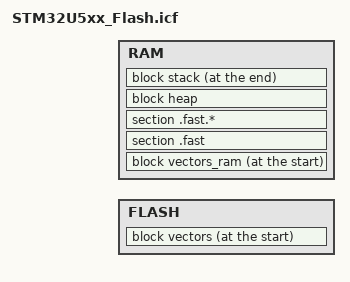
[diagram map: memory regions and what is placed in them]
/*********************************************************************
*                    SEGGER Microcontroller GmbH                     *
*                        The Embedded Experts                        *
**********************************************************************
*                                                                    *
*            (c) 2014 - 2024 SEGGER Microcontroller GmbH             *
*                                                                    *
*       www.segger.com     Support: support@segger.com               *
*                                                                    *
**********************************************************************
*                                                                    *
* All rights reserved.                                               *
*                                                                    *
* Redistribution and use in source and binary forms, with or         *
* without modification, are permitted provided that the following    *
* condition is met:                                                  *
*                                                                    *
* - Redistributions of source code must retain the above copyright   *
*   notice, this condition and the following disclaimer.             *
*                                                                    *
* THIS SOFTWARE IS PROVIDED BY THE COPYRIGHT HOLDERS AND             *
* CONTRIBUTORS "AS IS" AND ANY EXPRESS OR IMPLIED WARRANTIES,        *
* INCLUDING, BUT NOT LIMITED TO, THE IMPLIED WARRANTIES OF           *
* MERCHANTABILITY AND FITNESS FOR A PARTICULAR PURPOSE ARE           *
* DISCLAIMED. IN NO EVENT SHALL SEGGER Microcontroller BE LIABLE FOR *
* ANY DIRECT, INDIRECT, INCIDENTAL, SPECIAL, EXEMPLARY, OR           *
* CONSEQUENTIAL DAMAGES (INCLUDING, BUT NOT LIMITED TO, PROCUREMENT  *
* OF SUBSTITUTE GOODS OR SERVICES; LOSS OF USE, DATA, OR PROFITS;    *
* OR BUSINESS INTERRUPTION) HOWEVER CAUSED AND ON ANY THEORY OF      *
* LIABILITY, WHETHER IN CONTRACT, STRICT LIABILITY, OR TORT          *
* (INCLUDING NEGLIGENCE OR OTHERWISE) ARISING IN ANY WAY OUT OF THE  *
* USE OF THIS SOFTWARE, EVEN IF ADVISED OF THE POSSIBILITY OF SUCH   *
* DAMAGE.                                                            *
*                                                                    *
**********************************************************************
-------------------------- END-OF-HEADER -----------------------------

File    : STM32U5xx_Flash.icf
Purpose : STM32U5xx linker script for application placement in Flash,
          for use with the SEGGER Linker.
Maps    : STM32U535CBTx, STM32U535CBTxQ, STM32U535CBUx, STM32U535CBUxQ, 
          STM32U535CCTx, STM32U535CCTxQ, STM32U535CCUx, STM32U535CCUxQ, 
          STM32U535CETx, STM32U535CETxQ, STM32U535CEUx, STM32U535CEUxQ, 
          STM32U535JEYxQ, STM32U535NCYxQ, STM32U535NEYxQ, STM32U535RBIx, 
          STM32U535RBIxQ, STM32U535RBTx, STM32U535RBTxQ, STM32U535RCIx, 
          STM32U535RCIxQ, STM32U535RCTx, STM32U535RCTxQ, STM32U535REIx, 
          STM32U535REIxQ, STM32U535RETx, STM32U535RETxQ, STM32U535VCIx, 
          STM32U535VCIxQ, STM32U535VCTx, STM32U535VCTxQ, STM32U535VEIx, 
          STM32U535VEIxQ, STM32U535VETx, STM32U535VETxQ, STM32U545CETx, 
          STM32U545CETxQ, STM32U545CEUx, STM32U545CEUxQ, STM32U545JEYxQ, 
          STM32U545NEYxQ, STM32U545REIx, STM32U545REIxQ, STM32U545RETx, 
          STM32U545RETxQ, STM32U545VEIx, STM32U545VEIxQ, STM32U545VETx, 
          STM32U545VETxQ, STM32U575AGIx, STM32U575AGIxQ, STM32U575AIIx, 
          STM32U575AIIxQ, STM32U575CGTx, STM32U575CGTxQ, STM32U575CGUx, 
          STM32U575CGUxQ, STM32U575CITx, STM32U575CITxQ, STM32U575CIUx, 
          STM32U575CIUxQ, STM32U575OGYxQ, STM32U575OIYxQ, STM32U575QGIx, 
          STM32U575QGIxQ, STM32U575QIIx, STM32U575QIIxQ, STM32U575RGTx, 
          STM32U575RGTxQ, STM32U575RITx, STM32U575RITxQ, STM32U575VGTx, 
          STM32U575VGTxQ, STM32U575VITx, STM32U575VITxQ, STM32U575ZGTx, 
          STM32U575ZGTxQ, STM32U575ZITx, STM32U575ZITxQ, STM32U585AIIx, 
          STM32U585AIIxQ, STM32U585CITx, STM32U585CITxQ, STM32U585CIUx, 
          STM32U585CIUxQ, STM32U585OIYxQ, STM32U585QIIx, STM32U585QIIxQ, 
          STM32U585RITx, STM32U585RITxQ, STM32U585VITx, STM32U585VITxQ, 
          STM32U585ZITx, STM32U585ZITxQ, STM32U595AIHx, STM32U595AIHxQ, 
          STM32U595AJHx, STM32U595AJHxQ, STM32U595QIIx, STM32U595QIIxQ, 
          STM32U595QJIx, STM32U595QJIxQ, STM32U595RITx, STM32U595RITxQ, 
          STM32U595RJTx, STM32U595RJTxQ, STM32U595VITx, STM32U595VITxQ, 
          STM32U595VJTx, STM32U595VJTxQ, STM32U595ZITx, STM32U595ZITxQ, 
          STM32U595ZIYx, STM32U595ZIYxQ, STM32U595ZJTx, STM32U595ZJTxQ, 
          STM32U595ZJYxQ, STM32U599BJYxQ, STM32U599NIHxQ, STM32U599NJHxQ, 
          STM32U599VITxQ, STM32U599VJTx, STM32U599VJTxQ, STM32U599ZITxQ, 
          STM32U599ZIYxQ, STM32U599ZJTxQ, STM32U599ZJYxQ, STM32U5A5AJHx, 
          STM32U5A5AJHxQ, STM32U5A5QJIx, STM32U5A5QJIxQ, STM32U5A5RJTx, 
          STM32U5A5RJTxQ, STM32U5A5VJTx, STM32U5A5VJTxQ, STM32U5A5ZJTx, 
          STM32U5A5ZJTxQ, STM32U5A5ZJYxQ, STM32U5A9BJYxQ, STM32U5A9NJHxQ, 
          STM32U5A9VJTxQ, STM32U5A9ZJTxQ, STM32U5A9ZJYxQ, STM32U5F7VITx, 
          STM32U5F7VITxQ, STM32U5F7VJTx, STM32U5F7VJTxQ, STM32U5F9BJYxQ, 
          STM32U5F9NJHxQ, STM32U5F9VITxQ, STM32U5F9VJTxQ, STM32U5F9ZIJxQ, 
          STM32U5F9ZITxQ, STM32U5F9ZJJxQ, STM32U5F9ZJTxQ, STM32U5G7VJTx, 
          STM32U5G7VJTxQ, STM32U5G9BJYxQ, STM32U5G9NJHxQ, STM32U5G9VJTxQ, 
          STM32U5G9ZJJxQ, STM32U5G9ZJTxQ
Literature:
  [1]  SEGGER Linker User Guide (https://www.segger.com/doc/UM20005_Linker.html)
  [2]  SEGGER Linker Section Placement (https://wiki.segger.com/SEGGER_Linker_Script_Files)
*/

define memory with size = 4G;

//
// Combined regions per memory type
//
define region FLASH = FLASH1;
define region RAM   = RAM1 + RAM2;

//
// Block definitions
//
define block vectors                        { section .vectors };                                   // Vector table section
define block vectors_ram                    { section .vectors_ram };                               // Vector table section
define block ctors                          { section .ctors,     section .ctors.*, block with         alphabetical order { init_array } };
define block dtors                          { section .dtors,     section .dtors.*, block with reverse alphabetical order { fini_array } };
define block exidx                          { section .ARM.exidx, section .ARM.exidx.* };
define block tbss                           { section .tbss,      section .tbss.*  };
define block tdata                          { section .tdata,     section .tdata.* };
define block tls with fixed order           { block tbss, block tdata };
define block tdata_load                     { copy of block tdata };
define block heap           with auto size = __HEAPSIZE__,  alignment = 8, readwrite access { };
define block stack          with      size = __STACKSIZE__, alignment = 8, readwrite access { };
define block stack_process  with      size = __STACKSIZE_PROCESS__, alignment = 8, /* fill =0xCD, */ readwrite access { };
define block vram {};

//
// Explicit initialization settings for sections
// Packing options for initialize by copy: packing=auto/lzss/zpak/packbits
//
do not initialize                           { section .non_init, section .non_init.*, section .*.non_init, section .*.non_init.* };
do not initialize                           { section .no_init, section .no_init.*, section .*.no_init, section .*.no_init.* };   // Legacy sections, kept for backwards compatibility
do not initialize                           { section .noinit, section .noinit.*, section .*.noinit, section .*.noinit.* };       // Legacy sections, used by some SDKs/HALs
do not initialize                           { block vectors_ram };
initialize by copy with packing=auto        { section .data, section .data.*, section .*.data, section .*.data.* };               // Static data sections
initialize by copy with packing=auto        { section .fast, section .fast.*, section .*.fast, section .*.fast.* };               // "RAM Code" sections

initialize by calling __SEGGER_STOP_X_InitLimits    { section .data.stop.* };

#define USES_ALLOC_FUNC                                   \
  linked symbol malloc || linked symbol aligned_alloc ||  \
  linked symbol calloc || linked symbol realloc

initialize by calling __SEGGER_init_heap if USES_ALLOC_FUNC { block heap };                        // Init the heap if one is required
initialize by calling __SEGGER_init_ctors    { block ctors };                                      // Call constructors for global objects which need to be constructed before reaching main (if any). Make sure this is done after setting up heap.

//assert with warning "free() linked into application but there are no calls to an allocation function!" {
//  linked symbol free => USES_ALLOC_FUNC
//};

assert with error "heap is too small!"              { USES_ALLOC_FUNC => size  of block heap >= 48 };
assert with error "heap size not a multiple of 8!"  { USES_ALLOC_FUNC => size  of block heap % 8 == 0 };
assert with error "heap not correctly aligned!"     { USES_ALLOC_FUNC => start of block heap % 8 == 0 };

//
// Explicit placement in FLASHn
//
place in FLASH1                             { section .FLASH1, section .FLASH1.* };
//
// FLASH Placement
//
place at start of FLASH                     { block vectors };                                      // Vector table section
place in FLASH with minimum size order      { block tdata_load,                                     // Thread-local-storage load image
                                              block exidx,                                          // ARM exception unwinding block
                                              block ctors,                                          // Constructors block
                                              block dtors,                                          // Destructors block
                                              readonly,                                             // Catch-all for readonly data (e.g. .rodata, .srodata)
                                              readexec                                              // Catch-all for (readonly) executable code (e.g. .text)
                                            };

//
// Explicit placement in RAMn
//

place in RAM1                               { section .RAM1, section .RAM1.* };
place in RAM2                               { section .RAM2, section .RAM2.* };
//
// RAM Placement
//
place at start of RAM                       { block vectors_ram };
place in RAM1                                { block vram };                                      // Vector table section
place in RAM                                { section .fast, section .fast.* };                     // "ramfunc" section
place in RAM with auto order                { block tls,                                            // Thread-local-storage block
                                              readwrite,                                            // Catch-all for initialized/uninitialized data sections (e.g. .data, .noinit)
                                              zeroinit                                              // Catch-all for zero-initialized data sections (e.g. .bss)
                                            };
place in RAM                                { block heap };                                         // Heap reserved block
place at end of RAM                         { block stack };                                        // Stack reserved block at the end
